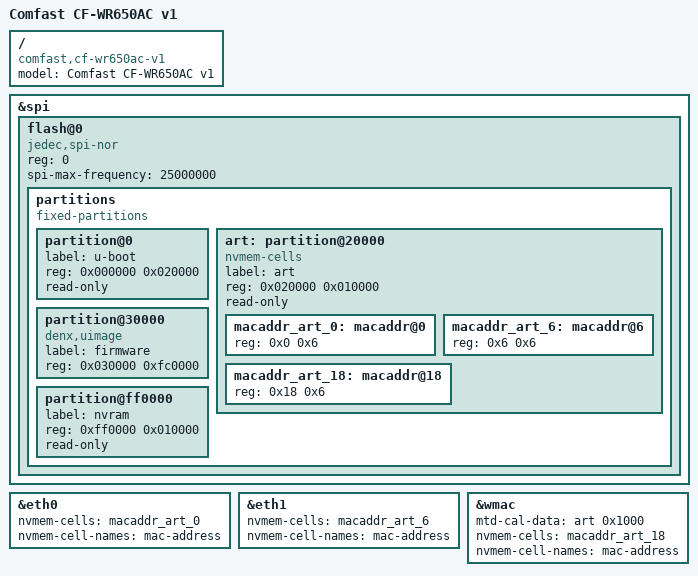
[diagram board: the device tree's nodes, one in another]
// SPDX-License-Identifier: GPL-2.0-or-later OR MIT

#include "qca9558_comfast_cf-wr650ac.dtsi"

/ {
	compatible = "comfast,cf-wr650ac-v1", "qca,qca9558";
	model = "Comfast CF-WR650AC v1";
};

&spi {
	status = "okay";

	flash@0 {
		compatible = "jedec,spi-nor";
		reg = <0>;
		spi-max-frequency = <25000000>;

		partitions {
			compatible = "fixed-partitions";
			#address-cells = <1>;
			#size-cells = <1>;

			partition@0 {
				label = "u-boot";
				reg = <0x000000 0x020000>;
				read-only;
			};

			art: partition@20000 {
				label = "art";
				reg = <0x020000 0x010000>;
				read-only;
			};

			partition@30000 {
				label = "firmware";
				compatible = "denx,uimage";
				reg = <0x030000 0xfc0000>;
			};

			partition@ff0000 {
				label = "nvram";
				reg = <0xff0000 0x010000>;
				read-only;
			};
		};
	};
};

&eth0 {
	nvmem-cells = <&macaddr_art_0>;
	nvmem-cell-names = "mac-address";
};

&eth1 {
	nvmem-cells = <&macaddr_art_6>;
	nvmem-cell-names = "mac-address";
};

&wmac {
	mtd-cal-data = <&art 0x1000>;

	nvmem-cells = <&macaddr_art_18>;
	nvmem-cell-names = "mac-address";
};

&art {
	compatible = "nvmem-cells";
	#address-cells = <1>;
	#size-cells = <1>;

	macaddr_art_0: macaddr@0 {
		reg = <0x0 0x6>;
	};

	macaddr_art_6: macaddr@6 {
		reg = <0x6 0x6>;
	};

	macaddr_art_18: macaddr@18 {
		reg = <0x18 0x6>;
	};
};
